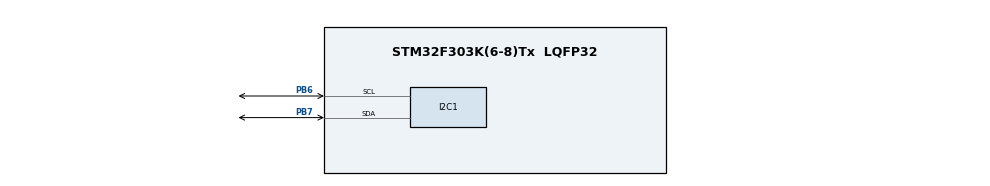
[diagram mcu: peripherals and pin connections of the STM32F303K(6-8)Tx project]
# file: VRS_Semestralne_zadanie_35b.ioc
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I2C1.I2C_Fall_Time=0
I2C1.I2C_Rise_Time=0
I2C1.OwnAddress=1
Mcu.Family=STM32F3
Mcu.Name=STM32F303K(6-8)Tx
Mcu.Package=LQFP32
NVIC.I2C1_EV_IRQn=true\:0\:0\:false\:false\:true\:true\:true\:true
NVIC.PriorityGroup=NVIC_PRIORITYGROUP_4
PB6.Mode=I2C
PB6.Signal=I2C1_SCL
PB7.Mode=I2C
PB7.Signal=I2C1_SDA
ProjectManager.HeapSize=0x200
ProjectManager.StackSize=0x400
ProjectManager.TargetToolchain=STM32CubeIDE
RCC.AHBFreq_Value=8000000
RCC.APB1Freq_Value=8000000
RCC.APB2Freq_Value=8000000
RCC.CortexFreq_Value=8000000
RCC.HSE_VALUE=8000000
RCC.HSI_VALUE=8000000
RCC.SYSCLKFreq_VALUE=8000000
board=custom

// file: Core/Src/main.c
/* USER CODE BEGIN Header */
/**
  ******************************************************************************
  * @file           : main.c
  * @brief          : Main program body
  ******************************************************************************
  * @attention
  *
  * Copyright (c) 2024 STMicroelectronics.
  * All rights reserved.
  *
  * This software is licensed under terms that can be found in the LICENSE file
  * in the root directory of this software component.
  * If no LICENSE file comes with this software, it is provided AS-IS.
  *
  ******************************************************************************
  */
/* USER CODE END Header */
#include "main.h"
#include "i2c.h"
#include "gpio.h"

/* USER CODE BEGIN Includes */
#include <stdio.h>
#include <math.h>
#include <string.h>
#include "VL53L1X_api.h"
#include "sensor.h"
#include "display_lib.h"
#include "decision.h"
#include "tdtd.h"

/* USER CODE END Includes */

/* USER CODE BEGIN PV */
uint16_t distance;
uint8_t rangeStatus;
uint8_t dataReady;
VL53L1X_ERROR status;
uint8_t sensorState;
uint8_t decisionError=0;
/* USER CODE END PV */

void SystemClock_Config(void);

int main(void)
{

  /* MCU Configuration--------------------------------------------------------*/

  /* Reset of all peripherals, Initializes the Flash interface and the Systick. */
  LL_APB2_GRP1_EnableClock(LL_APB2_GRP1_PERIPH_SYSCFG);
  LL_APB1_GRP1_EnableClock(LL_APB1_GRP1_PERIPH_PWR);

  /* System interrupt init*/
  NVIC_SetPriorityGrouping(NVIC_PRIORITYGROUP_4);

  /* SysTick_IRQn interrupt configuration */
  NVIC_SetPriority(SysTick_IRQn, NVIC_EncodePriority(NVIC_GetPriorityGrouping(),15, 0));

  /* Configure the system clock */
  SystemClock_Config();

  /* Initialize all configured peripherals */
  MX_GPIO_Init();
  MX_I2C1_Init();

  /* Infinite loop */
  /* USER CODE BEGIN WHILE */
	/* START register callback */
  	DispRegisterCallback_i2c_mread_single(i2c_master_read_single);
  	DispRegisterCallback_i2c_mread_multi(i2c_master_read_multi);
  	DispRegisterCallback_i2c_mwrite(i2c_master_write);
	/*RegisterCallback_i2c_mread_single(i2c_master_read_single);
	RegisterCallback_i2c_mread_multi(i2c_master_read_multi);
	RegisterCallback_i2c_mwrite(i2c_master_write);*/

	display_init();
	tester_rotation();

	/* END register callback */
	sensorState = 0;
	while(!sensorState) {
		status = VL53L1X_BootState(MAIN_SENSOR_ADDRESS, &sensorState);
		LL_mDelay(2);
	}
	status = VL53L1X_SensorInit(MAIN_SENSOR_ADDRESS);
	status = VL53L1X_StartRanging(MAIN_SENSOR_ADDRESS);
	while (1)
	{
    /* USER CODE END WHILE */
		//Forward 		- 0
		//Strong Left 	- 1
		//Left 			- 2
		//Backward 		- 3
		//Right 		- 4
		//Strong Right 	- 5
		switch(decisionLogicTesting()){
		case(0):display_forward();
		case(1):display_strongLeft();
		case(2):display_weakLeft();
		case(3):display_backward();
		case(4):display_weakRight();
		case(5):display_strongRight();
		default: decisionError=1;
		}
	}
}

void tester_rotation(){
	double laser_central[180] = {
	    185.11276569528204, 185.45175114501689, 186.0190317192506, 186.81810091594434, 187.85392319886282,
	    189.13301005003046, 190.66352142973125, 192.45539563439647, 194.52051148407952, 196.87288790804385,
	    199.5289273953531, 202.5077115236188, 205.83135898791014, 209.52545937747243, 213.61959960016173,
	    218.14800462198798, 223.15032047322262, 228.67257583746127, 234.7683697884273, 241.50034852647175,
	    248.94205497717985, 257.18026433808586, 266.3179598307596, 269.12654592127524, 261.0814578664557,
	    253.8036430145159, 247.21359549995805, 241.24358970078111, 235.83568067241944, 230.94010767585056,
	    226.51401013780801, 222.52038809503804, 218.92725570120965, 215.70694853551694, 212.8355544951827,
	    210.29244484765368, 208.05988717232066, 206.12272586997992, 204.46811897300617, 203.08532237714925,
	    201.9655145037239, 201.1016559127035, 200.48837961623482, 200.12190885976463, 200.0000000000004,
	    200.12190885976472, 200.4883796162347, 143.50158350258414, 107.779448014916, 86.38155724715472,
	    72.14601517116222, 62.00348241658122, 54.41932917814978, 48.541019662497035, 43.85706600244657,
	    40.04200743831041, 36.878900033613604, 34.217580490572914, 31.95081702284267, 30.000000000000057,
	    28.306198721998157, 26.824374749571177, 25.519524250561346, 24.364038682241244, 23.3358574029063,
	    22.417148247969294, 21.593348094385988, 20.852453865250425, 20.184490944095728, 19.581109339984323,
	    19.03527322608886, 18.541019662496865, 18.093269227558665, 17.68767605043155, 17.320508075688736,
	    16.98855076033567, 16.68902910712802, 16.41954417759075, 16.178021140163708, 15.962666587138756,
	    15.771933363573964, 15.604491537924048, 15.459204440248527, 15.335108922975508, 15.23139917828621,
	    15.147413587779283, 15.082624193452887, 15.036628471217568, 15.009143164482339, 14.999999999999886,
	    15.009143164482339, 15.036628471217568, 15.082624193452773, 15.147413587779226, 15.231399178286267,
	    15.33510892297545, 15.45920444024847, 15.604491537923991, 15.771933363574135, 15.962666587138699,
	    16.17802114016382, 16.41954417759075, 16.689029107127794, 16.98855076033567, 17.320508075688906,
	    17.68767605043155, 18.09326922755872, 18.54101966249698, 19.03527322608886, 19.58110933998421,
	    20.184490944095785, 20.852453865250425, 21.593348094385988, 22.41714824796918, 23.335857402906413,
	    24.36403868224147, 25.519524250561346, 26.824374749571348, 28.30619872199827, 30.000000000000455,
	    31.950817022843125, 34.21758049057354, 36.87890003361406, 40.04200743831058, 43.8570660024468,
	    48.541019662497206, 54.41932917814995, 62.00348241658202, 72.14601517116262, 86.38155724715546,
	    107.77944801491674, 143.50158350258624, 200.48837961623576, 200.12190885976563, 200.00000000000125,
	    200.12190885976557, 200.48837961623565, 201.10165591270447, 201.96551450372482, 203.08532237715013,
	    204.46811897300697, 206.12272586998074, 208.05988717232142, 210.29244484765454, 212.8355544951835,
	    215.70694853551777, 218.92725570121038, 222.52038809503878, 226.51401013780884, 230.94010767585127,
	    235.8356806724202, 241.24358970078202, 247.21359549995876, 253.8036430145166, 261.0814578664565,
	    269.126545921276, 266.3179598307605, 257.18026433808666, 248.9420549771806, 241.50034852647252,
	    234.76836978842815, 228.67257583746212, 223.15032047322353, 218.14800462198883, 213.61959960016253,
	    209.52545937747325, 205.83135898791087, 202.50771152361958, 199.52892739535386, 196.87288790804473,
	    194.5205114840804, 192.4553956343974, 190.66352142973207, 189.13301005003137, 187.85392319886378,
	    186.81810091594528, 186.01903171925153, 185.45175114501785, 185.11276569528306, 185.00000000000105
	};
	double laser_left[180] = {
			191.23074856073006, 193.23655861176707, 195.52197483964915, 198.1020623156691, 200.99437878649957,
			204.21929230489562, 207.8003656597757, 211.7648219884538, 216.14410993479686, 220.97459192709226,
			226.2983860341817, 232.1644010464841, 238.62961681649688, 245.7606787759479, 253.63589881803122,
			262.3477872027021, 271.14805481106265, 262.7177102208598, 255.10845717400187, 248.23217124822372,
			242.01408308231777, 236.39044528900456, 231.30668101656573, 226.7159030440703, 222.57772078594874,
			218.8572731284726, 215.5244400137592, 212.55319674911587, 209.92108326761232, 207.6087667778808,
			205.5996809660433, 203.87972854175268, 202.4370367358533, 201.26175756489877, 200.3459064293907,
			199.68323402133498, 199.26912766813206, 199.10053919973848, 199.17593724611044, 199.4952825938266,
			140.69659639368123, 97.36395329839755, 74.48608119618724, 60.3748180395146, 50.822489468798445,
			43.94295276683251, 38.76460904053646, 34.73605632958529, 31.52111667473718, 28.903182245420627,
			26.736412501073126, 24.919030905603623, 23.377865283617137, 22.058970812589294, 20.921715449307452,
			19.934922756211492, 19.07428300014438, 18.320571346569597, 17.65839416724806, 17.075289509561777,
			16.5610703219476, 16.107337364945376, 15.707112845212631, 15.354561325089305, 15.044774656324758,
			14.773604515454531, 14.537530772011383, 14.333557142974096, 14.15912785089151, 14.012060615675395,
			13.890492473216272, 13.792835763034418, 13.717742253942134, 13.664073844387675, 13.630878626830524,
			13.617371374226927, 13.622917713689034, 13.64702141362109, 13.689314337847694, 13.749548722062197,
			13.827591510875987, 13.923420562738729, 14.037122588927588, 14.168892744748728, 14.319035838612134,
			14.487969169995639, 14.676227052546292, 14.884467125717368, 15.113478609537017, 15.36419271471763,
			15.637695487123482, 15.93524344498069, 16.258282463404583, 16.608470479221918, 16.987704736792555,
			17.398154481916432, 17.842300248495242, 18.322981188307615, 18.843452291215442, 19.407453863284786,
			20.01929631826159, 20.683964256443375, 21.40724504397894, 22.19588879451436, 23.057808983457473,
			24.002336174108944, 25.04054192784464, 26.185656555204066, 27.453613949676058, 28.86377093134543,
			30.43986990525075, 32.21134650323227, 34.215135521134805, 36.498211617115246, 39.121238818493644,
			42.16393758256626, 45.73319262325003, 49.97568617689449, 55.098305729378446, 61.40254576259205,
			69.34554326886476, 79.65536722620394, 93.56661032327713, 113.35357044839529, 143.71652282262855,
			196.19258622037535, 199.26912766813308, 199.10053919973944, 199.17593724611135, 199.49528259382748,
			200.06002588931943, 200.87312760185048, 201.93910078057004, 203.2640777846221, 204.85590286290292,
			206.72425324369635, 208.88079230295511, 211.3393594610835, 214.11620277182718, 217.23026179088646,
			220.70351034810054, 224.5613714313601, 228.8332197061146, 233.5529914915843, 238.7599276386054,
			244.49948218558714, 250.82443958678252, 257.7962966787785, 265.48698377431026, 268.7071191063472,
			259.1031633699205, 250.4690777208379, 242.68982394715965, 235.66895210517205, 229.3250850380707,
			223.58917941473516, 218.40237113897902, 213.7142655673564, 209.48156992029996, 205.66699158295444,
			202.23834496723637, 199.16782345289045, 196.43140314139993, 194.00835277383806, 191.88082990076927,
			190.03354775589685, 188.45350063677515, 187.12973819621345, 186.05318108703048, 185.21647202068903,
			184.61385760156872, 184.24109736229013, 184.09539731237604, 184.17536607032503, 184.48099231637744,
			185.01364291207685, 185.77608161136632, 186.77250886260907, 188.00862379745305, 189.49171014818526
	};

	double laser_right[180] = {
			188.00862379745203, 186.77250886260805, 185.77608161136533, 185.0136429120759, 184.48099231637647,
			184.1753660703241, 184.09539731237524, 184.24109736228917, 184.61385760156782, 185.21647202068817,
			186.05318108702966, 187.12973819621274, 188.45350063677438, 190.033547755896, 191.88082990076856,
			194.0083527738373, 196.43140314139904, 199.16782345288962, 202.2383449672356, 205.66699158295353,
			209.48156992029917, 213.71426556735568, 218.4023711389781, 223.58917941473445, 229.32508503806986,
			235.66895210517134, 242.68982394715894, 250.46907772083716, 259.1031633699198, 268.7071191063463,
			265.4869837743095, 257.7962966787779, 250.82443958678184, 244.49948218558643, 238.75992763860472,
			233.5529914915836, 228.83321970611388, 224.56137143135942, 220.70351034809985, 217.23026179088572,
			214.11620277182644, 211.3393594610827, 208.88079230295438, 206.7242532436955, 204.85590286290218,
			203.2640777846213, 201.93910078056913, 200.87312760184963, 200.0600258893186, 199.49528259382657,
			199.1759372461104, 199.10053919973862, 199.26912766813214, 196.19258622037336, 143.71652282262755,
			113.35357044839475, 93.56661032327636, 79.65536722620283, 69.34554326886403, 61.40254576259172,
			55.09830572937824, 49.97568617689425, 45.7331926232501, 42.163937582566014, 39.121238818493524,
			36.498211617115295, 34.21513552113497, 32.21134650323242, 30.439869905250717, 28.863770931345528,
			27.453613949676104, 26.185656555203913, 25.04054192784453, 24.002336174109036, 23.05780898345737,
			22.19588879451432, 21.407245043979103, 20.68396425644333, 20.019296318261542, 19.407453863284893,
			18.843452291215375, 18.32298118830764, 17.84230024849519, 17.39815448191639, 16.987704736792576,
			16.608470479222, 16.258282463404583, 15.935243444980726, 15.637695487123581, 15.36419271471753,
			15.113478609536848, 14.884467125717444, 14.67622705254636, 14.487969169995516, 14.319035838612011,
			14.168892744748728, 14.037122588927613, 13.923420562738686, 13.827591510876042, 13.749548722062142,
			13.689314337847776, 13.647021413621172, 13.622917713688727, 13.617371374227007, 13.630878626830674,
			13.664073844387687, 13.717742253942093, 13.792835763034484, 13.890492473216225, 14.012060615675297,
			14.159127850891482, 14.333557142973973, 14.53753077201134, 14.773604515454409, 15.044774656324758,
			15.354561325089263, 15.707112845212409, 16.107337364945334, 16.56107032194775, 17.0752895095618,
			17.658394167248225, 18.32057134656984, 19.07428300014451, 19.934922756211428, 20.92171544930727,
			22.058970812589084, 23.377865283616973, 24.919030905603908, 26.7364125010733, 28.903182245420446,
			31.5211166747368, 34.73605632958517, 38.764609040536726, 43.94295276683271, 50.82248946879856,
			60.37481803951391, 74.48608119618713, 97.36395329839876, 140.69659639368257, 199.4952825938276,
			199.17593724611137, 199.1005391997394, 199.26912766813297, 199.68323402133586, 200.34590642939148,
			201.26175756489968, 202.43703673585418, 203.87972854175354, 205.59968096604422, 207.6087667778816,
			209.9210832676131, 212.5531967491168, 215.52444001376006, 218.8572731284734, 222.57772078594962,
			226.71590304407115, 231.30668101656644, 236.39044528900544, 242.0140830823186, 248.2321712482243,
			255.10845717400258, 262.71771022086045, 271.1480548110631, 262.3477872027031, 253.6358988180321,
			245.76067877594878, 238.62961681649773, 232.1644010464849, 226.29838603418258, 220.9745919270932,
			216.14410993479783, 211.76482198845483, 207.8003656597766, 204.2192923048966, 200.99437878650056,
			198.10206231567, 195.5219748396501, 193.236558611768, 191.23074856073103, 189.4917101481852
	};

	uint8_t RUN_INFINITE = 1;
	uint8_t cycle = 0;
	enum decision_type decs = forward;
	while (RUN_INFINITE){
		decs = make_decision(laser_left[cycle], laser_central[cycle], laser_right[cycle]);
		switch(decs){
		case(forward):display_forward(); break;
		case(strong_left):display_strongLeft();break;
		case(weak_left):display_weakLeft();break;
		case(backward):display_backward();break;
		case(weak_right):display_weakRight();break;
		case(strong_right):display_strongRight();break;
		default: display_none();break;
		}
		LL_mDelay(200);
		cycle++;
	}

}

void SystemClock_Config(void)
{
  LL_FLASH_SetLatency(LL_FLASH_LATENCY_0);
  while(LL_FLASH_GetLatency()!= LL_FLASH_LATENCY_0)
  {
  }
  LL_RCC_HSI_Enable();

   /* Wait till HSI is ready */
  while(LL_RCC_HSI_IsReady() != 1)
  {

  }
  LL_RCC_HSI_SetCalibTrimming(16);
  LL_RCC_SetAHBPrescaler(LL_RCC_SYSCLK_DIV_1);
  LL_RCC_SetAPB1Prescaler(LL_RCC_APB1_DIV_1);
  LL_RCC_SetAPB2Prescaler(LL_RCC_APB2_DIV_1);
  LL_RCC_SetSysClkSource(LL_RCC_SYS_CLKSOURCE_HSI);

   /* Wait till System clock is ready */
  while(LL_RCC_GetSysClkSource() != LL_RCC_SYS_CLKSOURCE_STATUS_HSI)
  {

  }
  LL_Init1msTick(8000000);
  LL_SetSystemCoreClock(8000000);
  LL_RCC_SetI2CClockSource(LL_RCC_I2C1_CLKSOURCE_HSI);
}

void Error_Handler(void)
{
  __disable_irq();
  while (1)
  {
  }
}
